AUTOSAR XML (schema 3-2-1)
package /HeatRegulator
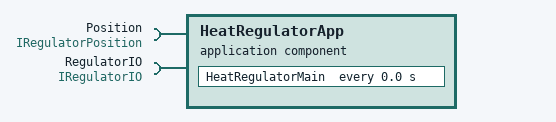
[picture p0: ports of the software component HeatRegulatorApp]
  application software component type HeatRegulatorApp
    require port Position: required-interface=IRegulatorPosition
    require port RegulatorIO: required-interface=IRegulatorIO
  swc implementation HeatRegulatorImplementation: behavior=HeatRegulatorBehavior
  internal behavior HeatRegulatorBehavior: component=HeatRegulatorApp
    timing event heatRegulatorTimingEvent: start-on-event=HeatRegulatorMain, period=0.0
    runnable HeatRegulatorMain: can-be-invoked-concurrently=true
      data read access dataReadAccess_1: data-element=RegulatorIO.RegulatorValue
      sync call syncCallPoint_toSetPosition: operation=Position.SetPosition
